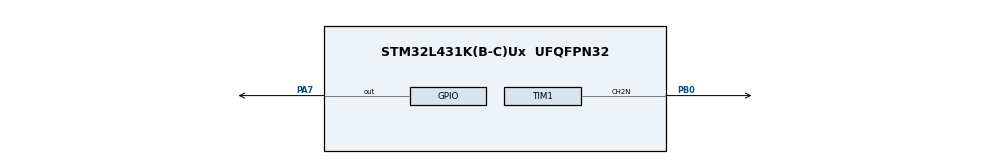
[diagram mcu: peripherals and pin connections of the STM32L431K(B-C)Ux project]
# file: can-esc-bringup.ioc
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Mcu.Family=STM32L4
Mcu.Name=STM32L431K(B-C)Ux
Mcu.Package=UFQFPN32
NVIC.PriorityGroup=NVIC_PRIORITYGROUP_4
PA13\ (JTMS-SWDIO).Mode=Trace_Asynchronous_SW
PA13\ (JTMS-SWDIO).Signal=SYS_JTMS-SWDIO
PA14\ (JTCK-SWCLK).Mode=Trace_Asynchronous_SW
PA14\ (JTCK-SWCLK).Signal=SYS_JTCK-SWCLK
PA7.Signal=GPIO_Output
PB0.Mode=PWM Generation2 CH2N
PB0.Signal=TIM1_CH2N
PB3\ (JTDO-TRACESWO).Mode=Trace_Asynchronous_SW
PB3\ (JTDO-TRACESWO).Signal=SYS_JTDO-SWO
ProjectManager.HeapSize=0x200
ProjectManager.StackSize=0x400
ProjectManager.TargetToolchain=STM32CubeIDE
RCC.HSE_VALUE=8000000
RCC.HSI48_VALUE=48000000
RCC.HSI_VALUE=16000000
RCC.LSE_VALUE=32768
RCC.MSI_VALUE=4000000
RCC.VCOOutputFreq_Value=32000000
TIM1.AutoReloadPreload=TIM_AUTORELOAD_PRELOAD_ENABLE
TIM1.Channel-PWM\ Generation2\ CH2N=TIM_CHANNEL_2
TIM1.Period=4000
VP_TIM1_VS_ClockSourceINT.Mode=Internal
board=custom

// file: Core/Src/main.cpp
/* USER CODE BEGIN Header */
/**
  ******************************************************************************
  * @file           : main.c
  * @brief          : Main program body
  ******************************************************************************
  * @attention
  *
  * Copyright (c) 2024 STMicroelectronics.
  * All rights reserved.
  *
  * This software is licensed under terms that can be found in the LICENSE file
  * in the root directory of this software component.
  * If no LICENSE file comes with this software, it is provided AS-IS.
  *
  ******************************************************************************
  */
/* USER CODE END Header */
#include "main.h"
#include "tim.h"
#include "gpio.h"

/* USER CODE BEGIN Includes */
#include <iostream>
#include <stdio.h>
/* USER CODE END Includes */

/* USER CODE BEGIN PD */
extern TIM_HandleTypeDef htim1;
/* USER CODE END PD */

void SystemClock_Config(void);

int main(void)
{

  /* MCU Configuration--------------------------------------------------------*/

  /* Reset of all peripherals, Initializes the Flash interface and the Systick. */
  HAL_Init();

  /* Configure the system clock */
  SystemClock_Config();

  /* Initialize all configured peripherals */
  MX_GPIO_Init();
  MX_TIM1_Init();
  /* USER CODE BEGIN 2 */

  HAL_TIM_PWM_Start(&htim1, TIM_CHANNEL_2);
  /* USER CODE END 2 */

  /* Infinite loop */
  /* USER CODE BEGIN WHILE */
  uint32_t PWM_WIDTH = 0;
  while (1)
  {

	  while(PWM_WIDTH < 4000) {
		  TIM1->CCR2 = PWM_WIDTH;
		  PWM_WIDTH += 1;
		  HAL_GPIO_TogglePin(GPIOA, GPIO_PIN_7);
		  HAL_Delay(100);
	  }
	  PWM_WIDTH = 0;
    /* USER CODE END WHILE */

  }
}

void SystemClock_Config(void)
{
  RCC_OscInitTypeDef RCC_OscInitStruct = {0};
  RCC_ClkInitTypeDef RCC_ClkInitStruct = {0};

  /** Configure the main internal regulator output voltage
  */
  if (HAL_PWREx_ControlVoltageScaling(PWR_REGULATOR_VOLTAGE_SCALE1) != HAL_OK)
  {
    Error_Handler();
  }

  /** Initializes the RCC Oscillators according to the specified parameters
  * in the RCC_OscInitTypeDef structure.
  */
  RCC_OscInitStruct.OscillatorType = RCC_OSCILLATORTYPE_MSI;
  RCC_OscInitStruct.MSIState = RCC_MSI_ON;
  RCC_OscInitStruct.MSICalibrationValue = 0;
  RCC_OscInitStruct.MSIClockRange = RCC_MSIRANGE_6;
  RCC_OscInitStruct.PLL.PLLState = RCC_PLL_NONE;
  if (HAL_RCC_OscConfig(&RCC_OscInitStruct) != HAL_OK)
  {
    Error_Handler();
  }

  /** Initializes the CPU, AHB and APB buses clocks
  */
  RCC_ClkInitStruct.ClockType = RCC_CLOCKTYPE_HCLK|RCC_CLOCKTYPE_SYSCLK
                              |RCC_CLOCKTYPE_PCLK1|RCC_CLOCKTYPE_PCLK2;
  RCC_ClkInitStruct.SYSCLKSource = RCC_SYSCLKSOURCE_MSI;
  RCC_ClkInitStruct.AHBCLKDivider = RCC_SYSCLK_DIV1;
  RCC_ClkInitStruct.APB1CLKDivider = RCC_HCLK_DIV1;
  RCC_ClkInitStruct.APB2CLKDivider = RCC_HCLK_DIV1;

  if (HAL_RCC_ClockConfig(&RCC_ClkInitStruct, FLASH_LATENCY_0) != HAL_OK)
  {
    Error_Handler();
  }
}

void Error_Handler(void)
{
  __disable_irq();
  while (1)
  {
  }
}
